# SN32F400 register map
Vendor: SONiX Technology Co., Ltd.; Series: SN32F400; File version: 1.1
CPU: CM0 r0p0, little endian, no MPU, no FPU, 2 interrupt priority bits
Registers are 32-bit, read-write, reset 0x0 unless marked. A register's access mark holds for its fields unless they carry their own. Offsets are from the block's base; [hi:lo] are bit positions; {n}, {i} and the like mark numbered series; 'fields as' and 'values as' point back to an identical list.

## SN_DMA0 — Direct Memory Access
Base 0x40072000
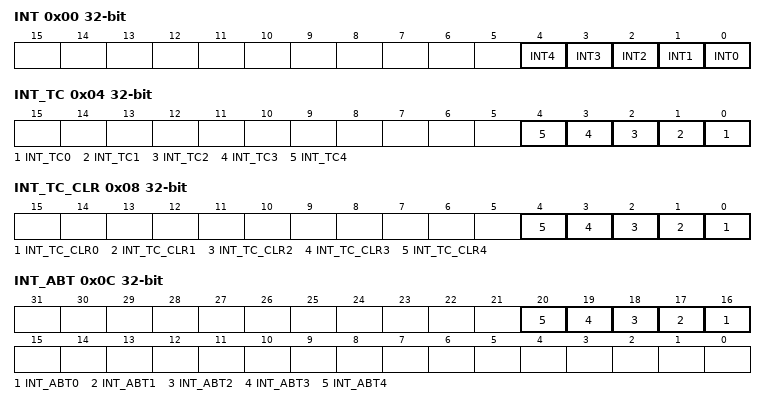
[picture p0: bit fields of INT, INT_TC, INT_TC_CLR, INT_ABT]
0x00 INT ro — Offset:0x00 DMA0 Interrupt Status register
  [n] INT{n} (n=0..4) — The result of INT_ABT{n} | INT_ERR{n} | INT_TC{n}
    0=No (Channel {n} has no pending interrupt); 1=Yes (Channel {n} has a pending interrupt)
0x04 INT_TC ro — Offset:0x04 DMA0 Transfer Complete Interrupt Status register
  [n] INT_TC{n} (n=0..4) — Status of the DMA terminal count interrupts after masking
    values as INT.INT0
0x08 INT_TC_CLR wo — Offset:0x08 DMA0 Transfer Complete Interrupt Status Clear register
  [n] INT_TC_CLR{n} (n=0..4) — Write 1 to clear the INT_TC{n} and TC{n} status
0x0C INT_ABT ro — Offset:0x0C DMA0 Abort Interrupt Status register
  [n+16] INT_ABT{n} (n=0..4) — Status of the DMA abort interrupts after masking
    0=No (Channel {n} has no pending interrupt); 1=Has (Channel {n} has a pending interrupt)
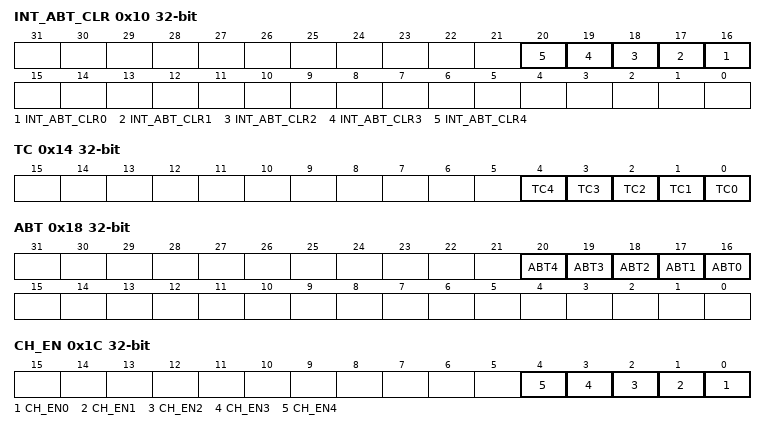
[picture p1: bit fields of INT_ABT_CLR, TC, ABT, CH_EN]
0x10 INT_ABT_CLR wo — Offset:0x10 DMA0 Abort Interrupt Status Clear register
  [n+16] INT_ABT_CLR{n} (n=0..4) — Write 1 to clear the INT_ABT{n} and ABT{n} status
0x14 TC ro — Offset:0x14 DMA0 Transfer Complete Status register
  [n] TC{n} (n=0..4) — Status of the DMA terminal count
    0=No (Channel {n} has no terminal count status); 1=Has (Channel {n} has a terminal count status)
0x18 ABT ro — Offset:0x18 DMA0 Abort Status register
  [n+16] ABT{n} (n=0..4) — Status of the DMA abort
    0=No (Channel {n} has no abort status); 1=Has (Channel {n} has an abort status)
0x1C CH_EN ro — Offset:0x1C DMA0 Channel Enable Status register
  [all] fields
    0=0b (CH_EN = 0); 1=1b (CH_EN = 1)
  [n] CH_EN{n} (n=0..4) — Status of the channel {n} CH_EN bit of C{n}_CSR register
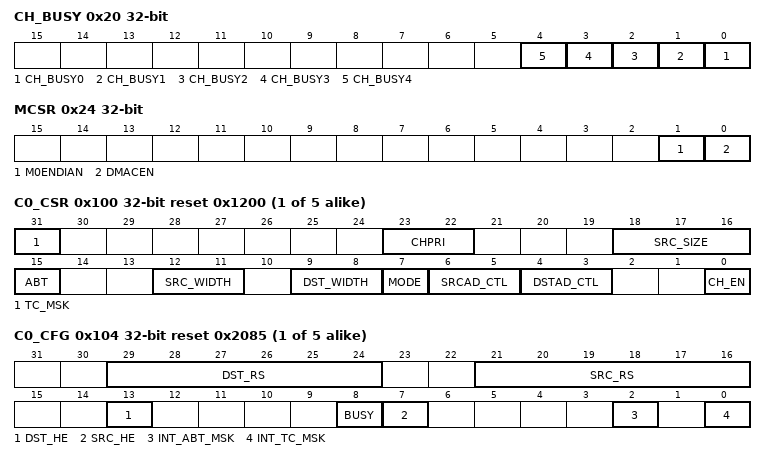
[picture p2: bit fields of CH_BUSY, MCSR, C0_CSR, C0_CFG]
0x20 CH_BUSY ro — Offset:0x20 DMA0 Channel Busy Status register
  [all] fields
    0=0b (BUSY = 0); 1=1b (BUSY = 1)
  [n] CH_BUSY{n} (n=0..4) — Status of the channel {n} BUSY bit of C{n}_CFG register
0x24 MCSR — Offset:0x24 DMA0 Main Configuration Status register
  [1] M0ENDIAN — AHB endian configuration
    0=Little-endian; 1=Big (Big-endian)
  [0] DMACEN — DMA controller enable
    0=Disable DMA Controller; 1=Enable DMA Controller
{0x100+0x20*i} C{i}_CSR reset 0x1200 (i=0..4) — Offset:{0x100+0x20*i} DMA0 Channel {i} control register
  [31] TC_MSK — Terminal count status mask for current transaction
    0=Disable (When terminal count happens, TC status register will be set); 1=Enable (When terminal count happens, TC status register will not be set)
  [23:22] CHPRI — Channel priority level
    0=00b (0: Lowest priority); 1=01b (1: 3rd high priority); 2=10b (2: 2nd high priority); 3=11b (3: Highest priority)
  [18:16] SRC_SIZE — Source burst size selection
    0=000b (Burst size = 1); 1=001b (Burst size = 4); 2=010b (Burst size = 8); 3=011b (Burst size = 16); 4=100b (Burst size = 32); 5=101b (Burst size = 64); 6=110b (Burst size = 128); 7=111b (Burst size = 256)
  [15] ABT wo — Transaction abort
  [12:11] SRC_WIDTH — Source transfer width
    0=00b (Transfer width is 8 bits); 1=01b (Transfer width is 16 bits); 2=10b (Transfer width is 32 bits)
  [9:8] DST_WIDTH — Destination transfer width
    values as SRC_WIDTH
  [7] MODE — Support Peripheral mode
    0=Normal mode; 1=Enable (Peripheral mode)
  [6:5] SRCAD_CTL — Source Address Control
    0=00b (Increment source address); 1=01b (Decrement source address); 2=10b (Fixed source address); 3=11b (Increment cyclic mode)
  [4:3] DSTAD_CTL — Destination Address Control
    0=00b (Increment destination address); 1=01b (Decrement destination address); 2=10b (Fixed destination address); 3=11b (Increment cyclic mode)
  [0] CH_EN — Channel Enable
    0=Disable DMA channel; 1=Enable DMA channel
{0x104+0x20*i} C{i}_CFG reset 0x2085 (i=0..4) — Offset:{0x104+0x20*i} DMA0 Channel {i} Configuration register
  [29:24] DST_RS — Destination DMA request select
    0=000000b (ADC); 2=000010b (SPI0 TX); 3=000011b (SPI0 RX); 6=000110b (UART0 TX); 7=000111b (UART0 RX); 8=001000b (UART1 TX); 9=001001b (UART1 RX); 14=001110b (I2C0); 16=010000b (CT16B0 CAP0); 17=010001b (CT16B0 MR9); 18=010010b (CT16B0 MR0); 19=010011b (CT16B0 MR1); 20=010100b (CT16B0 MR2); 21=010101b (CT16B0 MR3); 22=010110b (CT16B1 CAP0); 23=010111b (CT16B1 MR9); 24=011000b (CT16B1 MR0); 25=011001b (CT16B1 MR1); 26=011010b (CT16B1 MR2); 27=011011b (CT16B1 MR3); 42=101010b (CT16B5 CAP0); 43=101011b (CT16B5 MR9); 44=101100b (CT16B5 MR0); 45=101101b (CT16B5 MR1); 46=101110b (CT16B5 MR2); 47=101111b (CT16B5 MR3)
  [21:16] SRC_RS — Source DMA request select
    values as DST_RS
  [13] DST_HE — Destination Peripheral Mode enable
    0=Disable, hasn't request (memory); 1=Enable, has request (peripheral)
  [8] BUSY ro — The DMA channel is busy
    0=Not (The DMA channel is not Busy); 1=Busy (The DMA channel is Busy)
  [7] SRC_HE — Source Peripheral Mode enable
    values as DST_HE
  [2] INT_ABT_MSK — Channel abort interrupt mask
    0=Master 0 (No mask interrupt); 1=Master 1 (Mask interrupt)
  [0] INT_TC_MSK — Channel terminal count interrupt mask
    0=Disable (No mask interrupt); 1=Enable (Mask interrupt)
{0x108+0x20*i} C{i}_SRCADDR (i=0..4) — Offset:{0x108+0x20*i} DMA0 Channel {i} Source Address register
  [31:0] SRCADDR — Source starting address
{0x10C+0x20*i} C{i}_DSTADDR (i=0..4) — Offset:{0x10C+0x20*i} DMA0 Channel {i} Destination Address register
  [31:0] DSTADDR — Destination starting address
{0x114+0x20*i} C{i}_SIZE (i=0..4) — Offset:{0x114+0x20*i} DMA0 Channel {i} Transfer Size register
  [21:0] TOT_SIZE — Total transfer size for source
